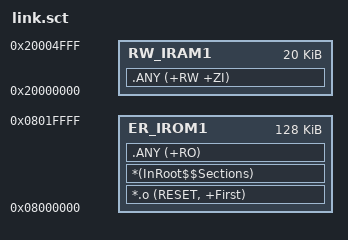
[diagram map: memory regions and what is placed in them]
; *************************************************************
; *** Scatter-Loading Description File generated by uVision ***
; *************************************************************

LR_IROM1 0x08000000 0x00020000  {    ; ROM1(起始地址0x08000000, 大小0x00020000)
  ER_IROM1 0x08000000 0x00020000  {  ; load address = execution address
    *.o (RESET, +First)
    *(InRoot$$Sections)
    .ANY (+RO)
  }
  RW_IRAM1 0x20000000 0x00005000  {  ; RAM1(起始地址0x20000000, 大小0x00005000)
    .ANY (+RW +ZI)
  }
}

